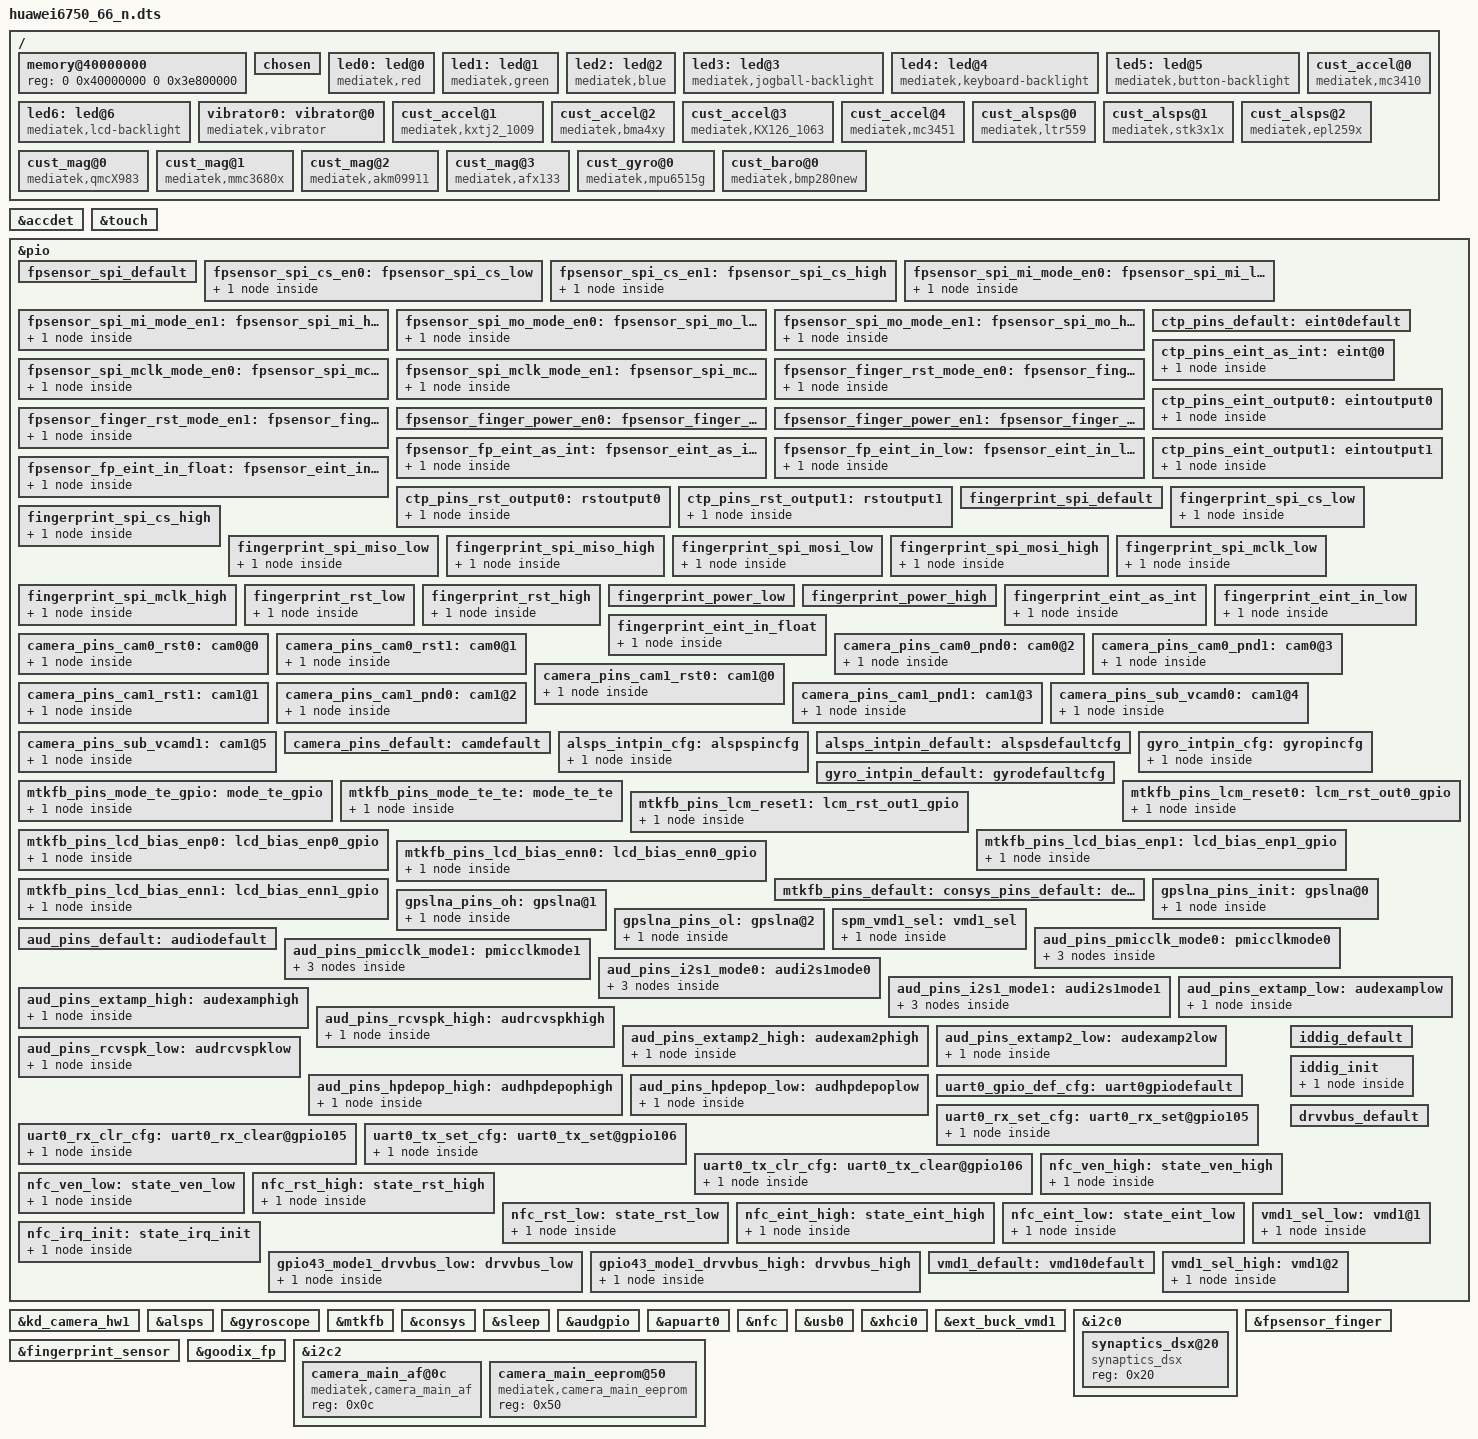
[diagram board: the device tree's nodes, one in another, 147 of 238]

/dts-v1/;

#include "mt6755.dtsi"
#include "cust.dtsi"
#include "ChipSailing_pin.dtsi"

/ {
    memory@40000000 {
        device_type = "memory";
        reg = <0 0x40000000 0 0x3e800000>;
    };
    /* chosen */
    chosen {
        bootargs = "console=tty0 console=ttyMT0,921600n1 root=/dev/ram initrd=0x44000000,0x4B434E loglevel=8";

        /* fpga may has no lk, we need to specify display info here */
        /* fb buffer is reserved using this dts by memory node above */
        atag,videolfb-fb_base_h = <0x0>;
        atag,videolfb-fb_base_l = <0x7E800000>;
        atag,videolfb-islcmfound = <1>;
        /* because no lk, so lcm is not inited */
        atag,videolfb-islcm_inited = <0>;
        atag,videolfb-fps= <6000>;
        atag,videolfb-vramSize= <0x01800000>;
        atag,videolfb-lcmname= "nt35695_fhd_dsi_cmd_truly_nt50358_drv";
    };
    led0:led@0 {
        compatible = "mediatek,red";
        led_mode = <3>;
        data = <1>;
        pwm_config = <0 0 0 0 0>;
    };
    led1:led@1 {
        compatible = "mediatek,green";
        led_mode = <3>;
        data = <2>;
        pwm_config = <0 0 0 0 0>;
    };
    led2:led@2 {
        compatible = "mediatek,blue";
        led_mode = <0>;
        data = <1>;
        pwm_config = <0 0 0 0 0>;
    };
    led3:led@3 {
        compatible = "mediatek,jogball-backlight";
        led_mode = <0>;
        data = <1>;
        pwm_config = <0 0 0 0 0>;
    };
    led4:led@4 {
        compatible = "mediatek,keyboard-backlight";
        led_mode = <0>;
        data = <1>;
        pwm_config = <0 0 0 0 0>;
    };
    led5:led@5 {
        compatible = "mediatek,button-backlight";
        led_mode = <0>;
        data = <1>;
        pwm_config = <0 0 0 0 0>;
    };
    led6:led@6 {
        compatible = "mediatek,lcd-backlight";
        led_mode = <4>;
        data = <1>;
        pwm_config = <0 0 0 0 0>;
    };
    vibrator0:vibrator@0 {
        compatible = "mediatek,vibrator";
        vib_timer = <25>;
        vib_limit = <9>;
        vib_vol= <5>;
    };
/*  start sensor */
    cust_accel@0 {
                compatible                              = "mediatek,mc3410";
                i2c_num                         = <1>;
                i2c_addr                                = <0x4c 0 0 0>;
                direction                               = <6>;
                power_id                                = <0xffff>;
                power_vol                               = <0>;
                firlen                                  = <0>;
                is_batch_supported                      = <0>;
                //calib_enable                    = <1>;
                //auto_calib_enable                       = <0>;
        };

    cust_accel@1 {
        compatible = "mediatek,kxtj2_1009";
        i2c_num = <1>;
        /* i2c_addr = <0x4c 0 0 0>; */
        direction = <4>;
        power_id = <0xffff>;
        power_vol = <0>;
        firlen = <0>;
        is_batch_supported = <0>;
        };
	cust_accel@2 {
        compatible = "mediatek,bma4xy";
        i2c_num = <1>;
        /* i2c_addr = <0x4c 0 0 0>; */
        direction = <4>;
        power_id = <0xffff>;
        power_vol = <0>;
        firlen = <0>;
        is_batch_supported = <0>;
        };

        cust_accel@3 {
        compatible = "mediatek,KX126_1063";
        i2c_num = <1>;
        //i2c_addr = <0x4c 0 0 0>;
        direction = <4>;
        power_id = <0xffff>;
        power_vol = <0>;
        firlen = <0>;
        is_batch_supported = <0>;
        };


        cust_accel@4 {
        compatible = "mediatek,mc3451";
        i2c_num = <1>;
        //i2c_addr = <0x4c 0 0 0>;
        direction = <4>;
        power_id = <0xffff>;
        power_vol = <0>;
        firlen = <0>;
        is_batch_supported = <0>;
        };
	cust_alsps@0 {
                compatible                              = "mediatek,ltr559";
                i2c_num                         = <1>;
                i2c_addr                                = <0x23 0 0 0>;
                polling_mode_ps                 = <0>;
                polling_mode_als                = <1>;
                power_id                                = <0xffff>;
                power_vol                               = <0>;
                als_level = <
                                        0  119  275  455  896  1507  2116    2661
                                        0  133  304   502  1004  2005  3058 4000
                                        0  133  304   502  1004  2005  3058 4000
                                        0  85  194  320  630  1059  1667    2210
                                        0  133  304   502  1004  2005  3058 4000
                                        0  133  304   502  1004  2005  3058 4000
                                         >;
                als_value = < 0  133  304  502   1004  2005  3058   4000 >;
                ps_threshold_high               =  <1000>;
                ps_threshold_low                =  <800>;
                is_batch_supported_ps   = <0>;
                is_batch_supported_als  = <0>;
                /*
                als_calib_enable = <1>;
                als_ch0_expect               =  <1000>;
                als_ch1_expect               =  <800>;
                */
                };

    cust_alsps@1 {
        compatible              = "mediatek,stk3x1x";
        i2c_num             = <1>;
        i2c_addr                = <0x48 0 0 0>;
        polling_mode_ps         = <0>;
        polling_mode_als        = <1>;
        power_id                = <0xffff>;
        power_vol               = <0>;
        als_level = <
                    0  44   90    212    442    762    922   1100
                    0  50   110   291    599    1295   2052   2807
                    0  74   150   348    698    1292   2205   2890
                    0  63   144   237    445    724     991   1231
                    0  72   163   258    560    1576   2400   3152
                    0  112  240   475    746    1719   2552   3333
                      >;
        als_value = < 0  100  200  500   1000  2000  3000   4000 >;
        state_val       =  <0>;
        psctrl_val      =  <0x31>;
        alsctrl_val = <0x38>;
        ledctrl_val = <0xFF>;
        wait_val        = <0xF>;
        ps_threshold_high       =  <1700>;
        ps_threshold_low        =  <1500>;
        is_batch_supported_ps   = <0>;
        is_batch_supported_als  = <0>;
        /*
        als_calib_enable = <1>;
        als_ch0_expect               =  <1000>;
        als_ch1_expect                =  <800>;
        */
        };
    cust_alsps@2 {
                compatible                              = "mediatek,epl259x";
                i2c_num                         = <1>;
                i2c_addr                                = <0x49 0 0 0>;
                polling_mode_ps                 = <0>;
                polling_mode_als                = <1>;
                power_id                                = <0xffff>;
                power_vol                               = <0>;
                als_level = <
                                        0  119  275  455  896  1507  2116    2661
                                        0  133  304   502  1004  2005  3058 4000
                                        0  133  304   502  1004  2005  3058 4000
                                        0  85  194  320  630  1059  1667    2210
                                        0  133  304   502  1004  2005  3058 4000
                                        0  133  304   502  1004  2005  3058 4000
                                         >;
                als_value = < 0  133  304  502   1004  2005  3058   4000 >;
                ps_threshold_high               =  <1000>;
                ps_threshold_low                =  <800>;
                als_threshold_high               =  <2000>;
                als_threshold_low                =  <1800>;
                is_batch_supported_ps   = <0>;
                is_batch_supported_als  = <0>;
                /*
                als_calib_enable = <1>;
                als_ch0_expect               =  <1000>;
                als_ch1_expect               =  <800>;
                */
                };

    cust_mag@0 {
        compatible                      = "mediatek,qmcX983";
        i2c_num                         = <1>;
        /* i2c_addr                     = <0x0F 0 0 0>; */
        direction                       = <3>;
        power_id                        = <0xffff>;
        power_vol                       = <0>;
        /* is_batch_supported           = <0>; */
        };

	cust_mag@1 {
        compatible                      = "mediatek,mmc3680x";
        i2c_num                         = <1>;
        /*i2c_addr                      = <0x0F 0 0 0>;*/
        direction                       = <2>;
        power_id                        = <0xffff>;
        power_vol                       = <0>;
        /* is_batch_supported           = <0>; */
        };
        cust_mag@2 {
        compatible                      = "mediatek,akm09911";
        i2c_num                         = <1>;
        /*i2c_addr                      = <0x0F 0 0 0>;*/
        direction                       = <2>;
        power_id                        = <0xffff>;
        power_vol                       = <0>;
        /* is_batch_supported           = <0>; */
        };

	cust_mag@3 {
        compatible                      = "mediatek,afx133";
        i2c_num                         = <1>;
        /*i2c_addr                      = <0x0F 0 0 0>;*/
        direction                       = <1>;
        power_id                        = <0xffff>;
        power_vol                       = <0>;
        /* is_batch_supported           = <0>; */
        };
    cust_gyro@0 {
    compatible          = "mediatek,mpu6515g";
    i2c_num             = <1>;
    /* i2c_addr         = <0x68 0 0 0>; */
    direction           = <6>;
    power_id            = <0xffff>;
    power_vol           = <0>;
    firlen              = <0>;
    is_batch_supported      = <0>;
    };

    cust_baro@0 {
    compatible          = "mediatek,bmp280new";
    i2c_num             = <1>;
    /* i2c_addr         = <0x68 0 0 0>; */
    direction           = <0>;
    power_id            = <0xffff>;
    power_vol           = <0>;
    firlen              = <32>;
    is_batch_supported      = <0>;
    };
/* end sensor */
};
&accdet {
        accdet-mic-vol = <7>;
        headset-mode-setting = <0x500 0x500 1 0x3F0 0x800 0x800 0x200>;
        accdet-plugout-debounce = <20>;
        /*1:ACC mode, 2:low cost without in bias, 6:low cost with in bias*/
        accdet-mic-mode = <1>;
        /*0--MD_MAX--UP_MAX--DW_MAX*/
        headset-three-key-threshold = <0 110 220 500>;
        /*0--MD_MAX--VOICE_MAX--UP_MAX--DW_MAX*/
        headset-four-key-threshold = <0 59 123 195 450>;
};

/* TOUCH start */
&touch {
    tpd-resolution = <720 1280>;
    use-tpd-button = <0>;
    tpd-key-num = <3>;
    tpd-key-local= <139 172 158 0>;
    tpd-key-dim-local = <90 883 100 40 230 883 100 40 370 883 100 40 0 0 0 0>;
    tpd-max-touch-num = <5>;
    tpd-filter-enable = <0>;
    tpd-filter-pixel-density = <146>;
    tpd-filter-custom-prameters = <0 0 0 0 0 0 0 0 0 0 0 0>;
    tpd-filter-custom-speed = <0 0 0>;
    pinctrl-names = "default", "state_eint_as_int", "state_eint_output0", "state_eint_output1",
        "state_rst_output0", "state_rst_output1";
    pinctrl-0 = <&ctp_pins_default>;
    pinctrl-1 = <&ctp_pins_eint_as_int>;
    pinctrl-2 = <&ctp_pins_eint_output0>;
    pinctrl-3 = <&ctp_pins_eint_output1>;
    pinctrl-4 = <&ctp_pins_rst_output0>;
    pinctrl-5 = <&ctp_pins_rst_output1>;
    status = "okay";
};
&pio {

    fpsensor_spi_default: fpsensor_spi_default {
    };

    fpsensor_spi_cs_en0: fpsensor_spi_cs_low {
        pins_cmd_dat {
            pins = <PINMUX_GPIO96__FUNC_SPI0_CSB>;
            slew-rate = <1>;
            output-low;
        };
    };
    fpsensor_spi_cs_en1: fpsensor_spi_cs_high {
        pins_cmd_dat {
            pins = <PINMUX_GPIO96__FUNC_SPI0_CSB>;
            slew-rate = <1>;
            output-high;
        };
    };
    fpsensor_spi_mi_mode_en0: fpsensor_spi_mi_low {
        pins_cmd_dat {
            pins = <PINMUX_GPIO95__FUNC_SPI0_MI>;
            slew-rate = <0>;
            bias-pull-up = <00>;
        };
    };
    fpsensor_spi_mi_mode_en1: fpsensor_spi_mi_high {
        pins_cmd_dat {
            pins = <PINMUX_GPIO95__FUNC_SPI0_MI>;
            bias-disable;
        };
    };
    fpsensor_spi_mo_mode_en0: fpsensor_spi_mo_low {
        pins_cmd_dat {
            pins = <PINMUX_GPIO97__FUNC_SPI0_MO>;
            slew-rate = <1>;
            output-low;
        };
    };
    fpsensor_spi_mo_mode_en1: fpsensor_spi_mo_high {
        pins_cmd_dat {
            pins = <PINMUX_GPIO97__FUNC_SPI0_MO>;
            slew-rate = <1>;
            output-high;
        };
    };
        fpsensor_spi_mclk_mode_en0: fpsensor_spi_mclk_low {
        pins_cmd_dat {
            pins = <PINMUX_GPIO98__FUNC_SPI0_CLK>;
            slew-rate = <1>;
            output-low;
        };
    };
    fpsensor_spi_mclk_mode_en1: fpsensor_spi_mclk_high {
        pins_cmd_dat {
            pins = <PINMUX_GPIO98__FUNC_SPI0_CLK>;
            slew-rate = <1>;
            output-high;
        };
    };
    fpsensor_finger_rst_mode_en0: fpsensor_finger_rst_low {
        pins_cmd_dat {
            pins = <PINMUX_GPIO18__FUNC_GPIO18>;
            slew-rate = <1>;
            output-low;
        };
    };
    fpsensor_finger_rst_mode_en1: fpsensor_finger_rst_high {
        pins_cmd_dat {
            pins = <PINMUX_GPIO18__FUNC_GPIO18>;
            slew-rate = <1>;
            output-high;
        };
    };
    fpsensor_finger_power_en0: fpsensor_finger_power_low {

    };
    fpsensor_finger_power_en1: fpsensor_finger_power_high {

    };
    fpsensor_fp_eint_as_int: fpsensor_eint_as_int {
        pins_cmd_dat {
            pins = <PINMUX_GPIO0__FUNC_GPIO0>;
            slew-rate = <0>;
            bias-disable;
        };
    };
    fpsensor_fp_eint_in_low: fpsensor_eint_in_low {
        pins_cmd_dat {
            pins = <PINMUX_GPIO0__FUNC_GPIO0>;
            slew-rate = <0>;
            bias-pull-down = <00>;
        };
    };
    fpsensor_fp_eint_in_float: fpsensor_eint_in_float {
        pins_cmd_dat {
            pins = <PINMUX_GPIO0__FUNC_GPIO0>;
            slew-rate = <0>;
            bias-disable;
        };
    };
/*
    fpsensor_finger_cs_mode_en0: fpsensor_finger_cs_low {
        pins_cmd_dat {
            pins = <PINMUX_GPIO96__FUNC_GPIO96>;
            slew-rate = <1>;
            output-low;
        };
    };
    fpsensor_finger_cs_mode_en1: fpsensor_finger_cs_high {
        pins_cmd_dat {
            pins = <PINMUX_GPIO96__FUNC_GPIO96>;
            slew-rate = <1>;
            output-high;
        };
    };
*/

    ctp_pins_default: eint0default {
    };
    ctp_pins_eint_as_int: eint@0 {
        pins_cmd_dat {
            pins = <PINMUX_GPIO1__FUNC_GPIO1>;
            slew-rate = <0>;
            bias-pull-up;
        };
    };
    ctp_pins_eint_output0: eintoutput0 {
        pins_cmd_dat {
            pins = <PINMUX_GPIO1__FUNC_GPIO1>;
            slew-rate = <1>;
            output-low;
        };
    };
    ctp_pins_eint_output1: eintoutput1 {
        pins_cmd_dat {
            pins = <PINMUX_GPIO1__FUNC_GPIO1>;
            slew-rate = <1>;
            output-high;
        };
    };
    ctp_pins_rst_output0: rstoutput0 {
        pins_cmd_dat {
            pins = <PINMUX_GPIO10__FUNC_GPIO10>;
            slew-rate = <1>;
            output-low;
        };
    };
    ctp_pins_rst_output1: rstoutput1 {
        pins_cmd_dat {
            pins = <PINMUX_GPIO10__FUNC_GPIO10>;
            slew-rate = <1>;
            output-high;
        };
    };
};
/* TOUCH end */
&pio {

    fingerprint_spi_default: fingerprint_spi_default {
    };

    fingerprint_spi_cs_low: fingerprint_spi_cs_low {
        pins_cmd_dat {
            pins = <PINMUX_GPIO96__FUNC_SPI0_CSB>;
            slew-rate = <1>;
            output-low;
        };
    };
    fingerprint_spi_cs_high: fingerprint_spi_cs_high {
        pins_cmd_dat {
            pins = <PINMUX_GPIO96__FUNC_SPI0_CSB>;
            slew-rate = <1>;
            output-high;
        };
    };
    fingerprint_spi_miso_low: fingerprint_spi_miso_low {
        pins_cmd_dat {
            pins = <PINMUX_GPIO95__FUNC_SPI0_MI>;
            slew-rate = <0>;
            bias-pull-up = <00>;
        };
    };
    fingerprint_spi_miso_high: fingerprint_spi_miso_high {
        pins_cmd_dat {
            pins = <PINMUX_GPIO95__FUNC_SPI0_MI>;
            bias-disable;
        };
    };
    fingerprint_spi_mosi_low: fingerprint_spi_mosi_low {
        pins_cmd_dat {
            pins = <PINMUX_GPIO97__FUNC_SPI0_MO>;
            slew-rate = <1>;
            output-low;
        };
    };
    fingerprint_spi_mosi_high: fingerprint_spi_mosi_high {
        pins_cmd_dat {
            pins = <PINMUX_GPIO97__FUNC_SPI0_MO>;
            slew-rate = <1>;
            output-high;
        };
    };
    fingerprint_spi_mclk_low: fingerprint_spi_mclk_low {
        pins_cmd_dat {
            pins = <PINMUX_GPIO98__FUNC_SPI0_CLK>;
            slew-rate = <1>;
            output-low;
        };
    };
    fingerprint_spi_mclk_high: fingerprint_spi_mclk_high {
        pins_cmd_dat {
            pins = <PINMUX_GPIO98__FUNC_SPI0_CLK>;
            slew-rate = <1>;
            output-high;
        };
    };
    fingerprint_rst_low: fingerprint_rst_low {
        pins_cmd_dat {
            pins = <PINMUX_GPIO18__FUNC_GPIO18>;
            slew-rate = <1>;
            output-low;
        };
    };
    fingerprint_rst_high: fingerprint_rst_high {
        pins_cmd_dat {
            pins = <PINMUX_GPIO18__FUNC_GPIO18>;
            slew-rate = <1>;
            output-high;
        };
    };
    fingerprint_power_low: fingerprint_power_low {

    };
    fingerprint_power_high: fingerprint_power_high {

    };
    fingerprint_eint_as_int: fingerprint_eint_as_int {
        pins_cmd_dat {
            pins = <PINMUX_GPIO0__FUNC_GPIO0>;
            slew-rate = <0>;
            bias-disable;
        };
    };
    fingerprint_eint_in_low: fingerprint_eint_in_low {
        pins_cmd_dat {
            pins = <PINMUX_GPIO0__FUNC_GPIO0>;
            slew-rate = <0>;
            bias-pull-down = <00>;
        };
    };
    fingerprint_eint_in_float: fingerprint_eint_in_float {
        pins_cmd_dat {
            pins = <PINMUX_GPIO0__FUNC_GPIO0>;
            slew-rate = <0>;
            bias-disable;
        };
    };
/*
    fpsensor_finger_cs_mode_en0: fpsensor_finger_cs_low {
        pins_cmd_dat {
            pins = <PINMUX_GPIO96__FUNC_GPIO96>;
            slew-rate = <1>;
            output-low;
        };
    };
    fpsensor_finger_cs_mode_en1: fpsensor_finger_cs_high {
        pins_cmd_dat {
            pins = <PINMUX_GPIO96__FUNC_GPIO96>;
            slew-rate = <1>;
            output-high;
        };
    };
*/
};
/* CAMERA GPIO standardization */
&pio {
    camera_pins_cam0_rst0: cam0@0 {
        pins_cmd_dat {
            pins = <PINMUX_GPIO110__FUNC_GPIO110>;
            slew-rate = <1>; /*direction 0:in, 1:out*/
            output-low;/*direction out used only. output_low or high*/
        };
    };
    camera_pins_cam0_rst1: cam0@1 {
        pins_cmd_dat {
            pins = <PINMUX_GPIO110__FUNC_GPIO110>;
            slew-rate = <1>;
            output-high;
        };
    };
    camera_pins_cam0_pnd0: cam0@2 {
        pins_cmd_dat {
            pins = <PINMUX_GPIO107__FUNC_GPIO107>;
            slew-rate = <1>;
            output-low;
        };
    };
    camera_pins_cam0_pnd1: cam0@3 {
        pins_cmd_dat {
            pins = <PINMUX_GPIO107__FUNC_GPIO107>;
            slew-rate = <1>;
            output-high;
        };
    };
    camera_pins_cam1_rst0: cam1@0 {
        pins_cmd_dat {
            pins = <PINMUX_GPIO111__FUNC_GPIO111>;
            slew-rate = <1>; /*direction 0:in, 1:out*/
            output-low;/*direction out used only. output_low or high*/
        };
    };
    camera_pins_cam1_rst1: cam1@1 {
        pins_cmd_dat {
            pins = <PINMUX_GPIO111__FUNC_GPIO111>;
            slew-rate = <1>;
            output-high;
        };
    };
    camera_pins_cam1_pnd0: cam1@2 {
        pins_cmd_dat {
            pins = <PINMUX_GPIO108__FUNC_GPIO108>;
            slew-rate = <1>;
            output-low;
        };
    };
    camera_pins_cam1_pnd1: cam1@3 {
        pins_cmd_dat {
            pins = <PINMUX_GPIO108__FUNC_GPIO108>;
            slew-rate = <1>;
            output-high;
        };
    };
    camera_pins_sub_vcamd0: cam1@4 {
        pins_cmd_dat {
            pins = <PINMUX_GPIO82__FUNC_GPIO82>;
            slew-rate = <1>;
            output-low;
        };
    };
    camera_pins_sub_vcamd1: cam1@5 {
        pins_cmd_dat {
            pins = <PINMUX_GPIO82__FUNC_GPIO82>;
            slew-rate = <1>;
            output-high;
        };
    };
    /*camera_pins_cam_ldo_vcama_0: cam@vcama0 {
    };
    camera_pins_cam_ldo_vcama_1: cam@vcama1 {
    };*/
    camera_pins_default: camdefault {
    };

};

&kd_camera_hw1 {
    pinctrl-names = "default",
            "cam0_rst0", "cam0_rst1", "cam0_pnd0", "cam0_pnd1",
            "cam1_rst0", "cam1_rst1", "cam1_pnd0", "cam1_pnd1",
            "cam_ldo_sub_vcamd_0", "cam_ldo_sub_vcamd_1";
            /*"cam2_rst0", "cam2_rst1", "cam2_pnd0", "cam2_pnd1",
            "cam_ldo_vcama_0", "cam_ldo_vcama_1";*/
    pinctrl-0 = <&camera_pins_default>;
    pinctrl-1 = <&camera_pins_cam0_rst0>;
    pinctrl-2 = <&camera_pins_cam0_rst1>;
    pinctrl-3 = <&camera_pins_cam0_pnd0>;
    pinctrl-4 = <&camera_pins_cam0_pnd1>;
    pinctrl-5 = <&camera_pins_cam1_rst0>;
    pinctrl-6 = <&camera_pins_cam1_rst1>;
    pinctrl-7 = <&camera_pins_cam1_pnd0>;
    pinctrl-8 = <&camera_pins_cam1_pnd1>;
    pinctrl-9 = <&camera_pins_sub_vcamd0>;
    pinctrl-10 = <&camera_pins_sub_vcamd1>;
    /* for main2 */
    /*pinctrl-9 = <&camera_pins_cam2_rst0>;
    pinctrl-10 = <&camera_pins_cam2_rst1>;
    pinctrl-11 = <&camera_pins_cam2_pnd0>;
    pinctrl-12 = <&camera_pins_cam2_pnd1>;*/
    /* for ldo control by gpio */
    /*pinctrl-13 = <&camera_pins_cam_ldo_vcama_0>;
    pinctrl-14 = <&camera_pins_cam_ldo_vcama_1>;*/
    status = "okay";

};
/* CAMERA GPIO end */

&pio {
    alsps_intpin_cfg: alspspincfg {

        pins_cmd_dat {
            pins = <PINMUX_GPIO6__FUNC_GPIO6>;
            slew-rate = <0>;
            bias-pull-up = <00>;
        };
    };

    alsps_intpin_default: alspsdefaultcfg {

    };

    gyro_intpin_cfg: gyropincfg {

        pins_cmd_dat {
            pins = <PINMUX_GPIO4__FUNC_GPIO4>;
            slew-rate = <0>;
            bias-pull-down = <00>;
        };
    };

    gyro_intpin_default: gyrodefaultcfg {

    };
};

&alsps {
    pinctrl-names = "pin_default", "pin_cfg";
    pinctrl-0 = <&alsps_intpin_default>;
    pinctrl-1 = <&alsps_intpin_cfg>;
    status = "okay";
};

&gyroscope {
    pinctrl-names = "pin_default", "pin_cfg";
    pinctrl-0 = <&gyro_intpin_default>;
    pinctrl-1 = <&gyro_intpin_cfg>;
    status = "okay";
};

/* DISPSYS GPIO standardization */
&pio {

    mtkfb_pins_mode_te_gpio: mode_te_gpio {
        pins_cmd_dat {
            pins = <PINMUX_GPIO44__FUNC_GPIO44>;
        };
    };

    mtkfb_pins_mode_te_te: mode_te_te {
        pins_cmd_dat {
            pins = <PINMUX_GPIO44__FUNC_DSI_TE>;
        };
    };

    mtkfb_pins_lcm_reset0: lcm_rst_out0_gpio {
        pins_cmd_dat {
            pins = <PINMUX_GPIO158__FUNC_LCM_RST>;
            slew-rate = <1>;
            output-low;
        };
    };

    mtkfb_pins_lcm_reset1: lcm_rst_out1_gpio {
        pins_cmd_dat {
            pins = <PINMUX_GPIO158__FUNC_LCM_RST>;
            slew-rate = <1>;
            output-high;
        };
    };

    mtkfb_pins_lcd_bias_enp0: lcd_bias_enp0_gpio {
        pins_cmd_dat {
            pins = <PINMUX_GPIO12__FUNC_GPIO12>;
            slew-rate = <1>;
            output-low;
        };
    };

    mtkfb_pins_lcd_bias_enp1: lcd_bias_enp1_gpio {
        pins_cmd_dat {
            pins = <PINMUX_GPIO12__FUNC_GPIO12>;
            slew-rate = <1>;
            output-high;
        };
    };
/* +add by ontim */
    mtkfb_pins_lcd_bias_enn0: lcd_bias_enn0_gpio {
        pins_cmd_dat {
            pins = <PINMUX_GPIO11__FUNC_GPIO11>;
            slew-rate = <1>;
            output-low;
        };
    };

    mtkfb_pins_lcd_bias_enn1: lcd_bias_enn1_gpio {
        pins_cmd_dat {
            pins = <PINMUX_GPIO11__FUNC_GPIO11>;
            slew-rate = <1>;
            output-high;
        };
    };
/* -add by ontim */

    mtkfb_pins_default: default {
    };
};

/* +add by ontim */
&mtkfb {
    pinctrl-names = "default", "mode_te_gpio", "mode_te_te", "lcm_rst_out0_gpio",
    "lcm_rst_out1_gpio", "lcd_bias_enp0_gpio", "lcd_bias_enp1_gpio", "lcd_bias_enn0_gpio", "lcd_bias_enn1_gpio";
    pinctrl-0 = <&mtkfb_pins_default>;
    pinctrl-1 = <&mtkfb_pins_mode_te_gpio>;
    pinctrl-2 = <&mtkfb_pins_mode_te_te>;
    pinctrl-3 = <&mtkfb_pins_lcm_reset0>;
    pinctrl-4 = <&mtkfb_pins_lcm_reset1>;
    pinctrl-5 = <&mtkfb_pins_lcd_bias_enp0>;
    pinctrl-6 = <&mtkfb_pins_lcd_bias_enp1>;
    pinctrl-7 = <&mtkfb_pins_lcd_bias_enn0>;
    pinctrl-8 = <&mtkfb_pins_lcd_bias_enn1>;
    status = "okay";
};/* DISPSYS GPIO standardization end */
/* -add by ontim */

/* CONSYS GPIO standardization */
&pio {
    consys_pins_default: default {
    };

    gpslna_pins_init: gpslna@0 {
        pins_cmd_dat {
            pins = <PINMUX_GPIO114__FUNC_GPIO114>;
            slew-rate = <0>;
            bias-disable;
            output-low;
        };
    };

    gpslna_pins_oh: gpslna@1 {
        pins_cmd_dat {
            pins = <PINMUX_GPIO114__FUNC_GPIO114>;
            slew-rate = <1>;
            output-high;
        };
    };

    gpslna_pins_ol: gpslna@2 {
        pins_cmd_dat {
            pins = <PINMUX_GPIO114__FUNC_GPIO114>;
            slew-rate = <1>;
            output-low;
        };
    };
};

&consys {
    pinctrl-names = "default", "gps_lna_state_init", "gps_lna_state_oh", "gps_lna_state_ol";
    pinctrl-0 = <&consys_pins_default>;
    pinctrl-1 = <&gpslna_pins_init>;
    pinctrl-2 = <&gpslna_pins_oh>;
    pinctrl-3 = <&gpslna_pins_ol>;
    status = "okay";
};
/* CONSYS end */

/* SPM GPIO standardization */
&pio {
    spm_pins_default: default {
    };

    spm_vmd1_sel: vmd1_sel {
        pins_cmd_dat {
            pins = <PINMUX_GPIO115__FUNC_GPIO115>;
        };
    };

};

&sleep{
    pinctrl-names = "default", "vmd1_sel";
    pinctrl-0 = <&spm_pins_default>;
    pinctrl-1 = <&spm_vmd1_sel>;
    status = "okay";
};
/* SPM end */

/* AUDIO GPIO standardization */
&audgpio {
    pinctrl-names = "default", "audpmicclk-mode0", "audpmicclk-mode1",
        "audi2s1-mode0", "audi2s1-mode1", "extamp-pullhigh", "extamp-pulllow",
        /*"extamp2-pullhigh", "extamp2-pulllow",*/ "rcvspk-pullhigh",
        "rcvspk-pulllow","hpdepop-pullhigh","hpdepop-pulllow";
    pinctrl-0 = <&aud_pins_default>;
    pinctrl-1 = <&aud_pins_pmicclk_mode0>;
    pinctrl-2 = <&aud_pins_pmicclk_mode1>;
    pinctrl-3 = <&aud_pins_i2s1_mode0>;
    pinctrl-4 = <&aud_pins_i2s1_mode1>;
    pinctrl-5 = <&aud_pins_extamp_high>;
    pinctrl-6 = <&aud_pins_extamp_low>;
/*  pinctrl-7 = <&aud_pins_extamp2_high>;
    pinctrl-8 = <&aud_pins_extamp2_low>;  */
    pinctrl-7 = <&aud_pins_rcvspk_high>;
    pinctrl-8 = <&aud_pins_rcvspk_low>;
    pinctrl-9 = <&aud_pins_hpdepop_high>;
    pinctrl-10 = <&aud_pins_hpdepop_low>;
    status = "okay";
};

&pio {
    aud_pins_default: audiodefault {
    };

    aud_pins_pmicclk_mode0: pmicclkmode0 {
        pins_cmd0_dat {
            pins = <PINMUX_GPIO149__FUNC_GPIO149>;
        };
        pins_cmd1_dat {
            pins = <PINMUX_GPIO150__FUNC_GPIO150>;
            slew-rate = <0>;
            bias-pull-up = <00>;
        };
        pins_cmd2_dat {
            pins = <PINMUX_GPIO151__FUNC_GPIO151>;
        };
    };

    aud_pins_pmicclk_mode1: pmicclkmode1 {
        pins_cmd0_dat {
            pins = <PINMUX_GPIO149__FUNC_AUD_CLK_MOSI>;
        };
        pins_cmd1_dat {
            pins = <PINMUX_GPIO150__FUNC_AUD_DAT_MOSI>;
        };
        pins_cmd2_dat {
            pins = <PINMUX_GPIO151__FUNC_AUD_DAT_MISO>;
        };
    };

    aud_pins_i2s1_mode0: audi2s1mode0 {
        pins_cmd0_dat {
            pins = <PINMUX_GPIO7__FUNC_GPIO7>;
        };
        pins_cmd1_dat {
            pins = <PINMUX_GPIO6__FUNC_GPIO6>;
        };
        pins_cmd2_dat {
            pins = <PINMUX_GPIO5__FUNC_GPIO5>;
        };
    };

    aud_pins_i2s1_mode1: audi2s1mode1 {
        pins_cmd0_dat {
            pins = <PINMUX_GPIO7__FUNC_I2S0_DI>;
        };
        pins_cmd1_dat {
            pins = <PINMUX_GPIO6__FUNC_I2S0_LRCK>;
        };
        pins_cmd2_dat {
            pins = <PINMUX_GPIO5__FUNC_I2S0_BCK>;
        };
    };

    aud_pins_extamp_high: audexamphigh {
        pins_cmd_dat {
            pins = <PINMUX_GPIO22__FUNC_GPIO22>;
            slew-rate = <1>;
            output-high;
        };
    };

    aud_pins_extamp_low: audexamplow {
        pins_cmd_dat {
            pins = <PINMUX_GPIO22__FUNC_GPIO22>;
            slew-rate = <1>;
            output-low;
        };
    };
/*
    aud_pins_extamp2_high: audexam2phigh {
        pins_cmd_dat {
            pins = <PINMUX_GPIO54__FUNC_GPIO54>;
            slew-rate = <1>;
            output-high;
        };
    };
    aud_pins_extamp2_low: audexamp2low {
        pins_cmd_dat {
            pins = <PINMUX_GPIO54__FUNC_GPIO54>;
            slew-rate = <1>;
            output-low;
        };
    };
*/
    aud_pins_rcvspk_high: audrcvspkhigh {
        pins_cmd_dat {
            pins = <PINMUX_GPIO120__FUNC_GPIO120>;
            slew-rate = <1>;
            output-high;
        };
    };

    aud_pins_extamp2_high: audexam2phigh {
        pins_cmd_dat {
            pins = <PINMUX_GPIO54__FUNC_GPIO54>;
            slew-rate = <1>;
            output-high;
        };
    };
    aud_pins_extamp2_low: audexamp2low {
        pins_cmd_dat {
            pins = <PINMUX_GPIO54__FUNC_GPIO54>;
            slew-rate = <1>;
            output-low;
        };
    };

    aud_pins_rcvspk_high: audrcvspkhigh {
        pins_cmd_dat {
            pins = <PINMUX_GPIO120__FUNC_GPIO120>;
            slew-rate = <1>;
            output-high;
        };
    };

    aud_pins_rcvspk_low: audrcvspklow {
        pins_cmd_dat {
            pins = <PINMUX_GPIO120__FUNC_GPIO120>;
            slew-rate = <1>;
            output-low;
        };
    };

    aud_pins_hpdepop_high: audhpdepophigh {
        pins_cmd_dat {
            pins = <PINMUX_GPIO24__FUNC_GPIO24>;
            slew-rate = <1>;
            output-high;
        };
    };

    aud_pins_hpdepop_low: audhpdepoplow {
        pins_cmd_dat {
            pins = <PINMUX_GPIO24__FUNC_GPIO24>;
            slew-rate = <1>;
            output-low;
        };
    };
};
/* AUDIO end */

/* UART GPIO */
&apuart0 {
    pinctrl-names = "uart0_gpio_default",
            "uart0_rx_set",
            "uart0_rx_clear",
            "uart0_tx_set",
            "uart0_tx_clear";
    pinctrl-0 = <&uart0_gpio_def_cfg>;
    pinctrl-1 = <&uart0_rx_set_cfg>;
    pinctrl-2 = <&uart0_rx_clr_cfg>;
    pinctrl-3 = <&uart0_tx_set_cfg>;
    pinctrl-4 = <&uart0_tx_clr_cfg>;
    status = "okay";
};

&pio {
    /* UART GPIO Settings - Start */
    /* UART0: rx set, rx clear, tx clear, tx clear*/
    uart0_gpio_def_cfg:uart0gpiodefault {

    };
    uart0_rx_set_cfg:uart0_rx_set@gpio105 {
        pins_cmd_dat {
            pins = <PINMUX_GPIO105__FUNC_URXD0>;
        };
    };
    uart0_rx_clr_cfg:uart0_rx_clear@gpio105  {
        pins_cmd_dat {
            pins = <PINMUX_GPIO105__FUNC_GPIO105>;
            slew-rate = <1>;
            output-high;
        };
    };
    uart0_tx_set_cfg:uart0_tx_set@gpio106  {
        pins_cmd_dat {
            pins = <PINMUX_GPIO106__FUNC_UTXD0>;
        };
    };
    uart0_tx_clr_cfg:uart0_tx_clear@gpio106  {
        pins_cmd_dat {
            pins = <PINMUX_GPIO106__FUNC_GPIO106>;
            slew-rate = <1>;
            output-high;
        };
    };
};/* UART GPIO end */

/* NFC GPIO standardization */
&pio {
    nfc_default: default {

    };

    nfc_ven_high: state_ven_high {
        pins_cmd_dat {
            pins = <PINMUX_GPIO28__FUNC_GPIO28>;
            slew-rate = <1>;
            output-high;
        };
    };

    nfc_ven_low: state_ven_low {
        pins_cmd_dat {
            pins = <PINMUX_GPIO28__FUNC_GPIO28>;
            slew-rate = <1>;
            output-low;
        };
    };

    nfc_rst_high: state_rst_high {
        pins_cmd_dat {
            pins = <PINMUX_GPIO25__FUNC_GPIO25>;
            slew-rate = <1>;
            output-high;
        };
    };

    nfc_rst_low: state_rst_low {
        pins_cmd_dat {
            pins = <PINMUX_GPIO25__FUNC_GPIO25>;
            slew-rate = <1>;
            output-low;
        };
    };

    nfc_eint_high: state_eint_high {
        pins_cmd_dat {
            pins = <PINMUX_GPIO27__FUNC_GPIO27>;
            slew-rate = <1>;
            output-high;
        };
    };

    nfc_eint_low: state_eint_low {
        pins_cmd_dat {
            pins = <PINMUX_GPIO27__FUNC_GPIO27>;
            slew-rate = <1>;
            output-low;
        };
    };

    nfc_irq_init: state_irq_init {
        pins_cmd_dat {
            pins = <PINMUX_GPIO26__FUNC_GPIO26>;
            slew-rate = <0>;
            bias-pull-down = <00>;
        };
    };
};

&nfc {
    pinctrl-names = "default", "ven_high", "ven_low", "rst_high", "rst_low", "eint_high", "eint_low", "irq_init";
    pinctrl-0 = <&nfc_default>;
    pinctrl-1 = <&nfc_ven_high>;
    pinctrl-2 = <&nfc_ven_low>;
    pinctrl-3 = <&nfc_rst_high>;
    pinctrl-4 = <&nfc_rst_low>;
    pinctrl-5 = <&nfc_eint_high>;
    pinctrl-6 = <&nfc_eint_low>;
    pinctrl-7 = <&nfc_irq_init>;
    status = "okay";
};
/* NFC end */




&pio {
    iddig_default: iddig_default {
    };

    iddig_init: iddig_init {
        pins_cmd_dat {
            pins = <PINMUX_GPIO23__FUNC_IDDIG>;
            slew-rate = <0>;
            bias-pull-up = <00>;
        };
    };
};

&pio {
    drvvbus_default: drvvbus_default {
    };

    gpio43_mode1_drvvbus_low: drvvbus_low {
        pins_cmd_dat {
            pins = <PINMUX_GPIO43__FUNC_USB_DRVVBUS>;
            slew-rate = <1>;
            output-low;
        };
    };

    gpio43_mode1_drvvbus_high: drvvbus_high {
        pins_cmd_dat {
            pins = <PINMUX_GPIO43__FUNC_USB_DRVVBUS>;
            slew-rate = <1>;
            output-high;
        };
    };
};

&usb0 {
    pinctrl-names = "iddig_default", "iddig_init";
    pinctrl-0 = <&iddig_default>;
    pinctrl-1 = <&iddig_init>;
    status = "okay";
};

&xhci0 {
    pinctrl-names = "drvvbus_default", "drvvbus_low", "drvvbus_high";
    pinctrl-0 = <&drvvbus_default>;
    pinctrl-1 = <&gpio43_mode1_drvvbus_low>;
    pinctrl-2 = <&gpio43_mode1_drvvbus_high>;
    status = "okay";
};
/*
&i2c1 {

    gyro@68 {
        compatible = "mediatek,gyro";
        reg = <0x69>;
        status = "okay";
    };

    gsensor@68 {
        compatible = "mediatek,gsensor";
        reg = <0x68>;
        status = "okay";
    };
};
*/
&ext_buck_vmd1 {
    pinctrl-names = "default", "vmd1_sel_low", "vmd1_sel_high";

    pinctrl-0 = <&vmd1_default>;
    pinctrl-1 = <&vmd1_sel_low>;
    pinctrl-2 = <&vmd1_sel_high>;
};

&pio {
    vmd1_default: vmd10default {
    };

    vmd1_sel_low: vmd1@1 {
        pins_cmd_dat {
            pins = <PINMUX_GPIO115__FUNC_GPIO115>;
            slew-rate = <1>;
            output-low;
        };
    };

    vmd1_sel_high: vmd1@2 {
        pins_cmd_dat {
            pins = <PINMUX_GPIO115__FUNC_GPIO115>;
            slew-rate = <1>;
            output-high;
        };
    };
};

/* add by ontim for I2C devices*/
&i2c0 {
    synaptics_dsx@20 {
        compatible = "synaptics_dsx";
        reg = <0x20>;
        status = "okay";
    };
};


&fpsensor_finger {
    interrupt-parent = <&eintc>;
    interrupts = <0 IRQ_TYPE_EDGE_RISING>;
    debounce = <0 0>;
    pinctrl-names = "fpsensor_spi_default", "fpsensor_spi_cs_low","fpsensor_spi_cs_high","fpsensor_spi_mi_low","fpsensor_spi_mi_high",
                    "fpsensor_spi_mo_low","fpsensor_spi_mo_high","fpsensor_spi_mclk_low","fpsensor_spi_mclk_high",
                    "fpsensor_finger_rst_low","fpsensor_finger_rst_high","fpsensor_finger_power_low","fpsensor_finger_power_high",
                    "fpsensor_eint","fpsensor_eint_in_low","fpsensor_eint_in_float"/*,"fpsensor_finger_cs_low","fpsensor_finger_cs_high"*/;
    pinctrl-0 = <&fpsensor_spi_default>;
    pinctrl-1 = <&fpsensor_spi_cs_en0>;
    pinctrl-2 = <&fpsensor_spi_cs_en1>;
    pinctrl-3 = <&fpsensor_spi_mi_mode_en0>;
    pinctrl-4 = <&fpsensor_spi_mi_mode_en1>;
    pinctrl-5 = <&fpsensor_spi_mo_mode_en0>;
    pinctrl-6 = <&fpsensor_spi_mo_mode_en1>;
    pinctrl-7 = <&fpsensor_spi_mclk_mode_en0>;
    pinctrl-8 = <&fpsensor_spi_mclk_mode_en1>;
    pinctrl-9 = <&fpsensor_finger_rst_mode_en0>;
    pinctrl-10 = <&fpsensor_finger_rst_mode_en1>;
    pinctrl-11 = <&fpsensor_finger_power_en0>;
    pinctrl-12 = <&fpsensor_finger_power_en1>;
    pinctrl-13 = <&fpsensor_fp_eint_as_int>;
    pinctrl-14 = <&fpsensor_fp_eint_in_low>;
    pinctrl-15 = <&fpsensor_fp_eint_in_float>;
    /*pinctrl-16 = <&fpsensor_finger_cs_mode_en0>;
    pinctrl-17 = <&fpsensor_finger_cs_mode_en1>;*/
    status = "okay";
};
&fingerprint_sensor {
    interrupt-parent = <&eintc>;
    interrupts = <0 IRQ_TYPE_EDGE_RISING>;
    debounce = <0 0>;
        fingerprint,navigation_adjust1 = <1>;

    pinctrl-names = "fingerprint_spi_default", "fingerprint_spi_cs_low","fingerprint_spi_cs_high","fingerprint_spi_miso_low","fingerprint_spi_miso_high",
                    "fingerprint_spi_mosi_low","fingerprint_spi_mosi_high","fingerprint_spi_mclk_low","fingerprint_spi_mclk_high",
                    "fingerprint_rst_low","fingerprint_rst_high","fingerprint_power_low","fingerprint_power_high",
                    "fingerprint_eint_as_int","fingerprint_eint_in_low","fingerprint_eint_in_float";
    pinctrl-0 = <&fingerprint_spi_default>;
    pinctrl-1 = <&fingerprint_spi_cs_low>;
    pinctrl-2 = <&fingerprint_spi_cs_high>;
    pinctrl-3 = <&fingerprint_spi_miso_low>;
    pinctrl-4 = <&fingerprint_spi_miso_high>;
    pinctrl-5 = <&fingerprint_spi_mosi_low>;
    pinctrl-6 = <&fingerprint_spi_mosi_high>;
    pinctrl-7 = <&fingerprint_spi_mclk_low>;
    pinctrl-8 = <&fingerprint_spi_mclk_high>;
    pinctrl-9 = <&fingerprint_rst_low>;
    pinctrl-10 = <&fingerprint_rst_high>;
    pinctrl-11 = <&fingerprint_power_low>;
    pinctrl-12 = <&fingerprint_power_high>;
    pinctrl-13 = <&fingerprint_eint_as_int>;
    pinctrl-14 = <&fingerprint_eint_in_low>;
    pinctrl-15 = <&fingerprint_eint_in_float>;
    status = "okay";
};
&goodix_fp {
    pinctrl-names = "cs_finger_pins_default", "cs_finger_reset_en0","cs_finger_reset_en1","cs_finger_spi0_mi_as_spi0_mi","cs_finger_spi0_mi_as_gpio",
                    "cs_finger_spi0_mo_as_spi0_mo","cs_finger_spi0_mo_as_gpio","cs_finger_spi0_clk_as_spi0_clk","cs_finger_spi0_clk_as_gpio","cs_finger_spi0_cs_as_spi0_cs",
                    "cs_finger_spi0_cs_as_gpio","cs_finger_int_as_int","cs_finger_eint_pull_down","cs_finger_eint_pull_disable","cs_finger_pwr_off", "cs_finger_pwr_on";
    pinctrl-0 = <&cs_finger_pins_default>;
    pinctrl-1 = <&cs_finger_reset_en0>;
    pinctrl-2 = <&cs_finger_reset_en1>;
    pinctrl-3 = <&cs_finger_spi0_mi_as_spi0_mi>;
    pinctrl-4 = <&cs_finger_spi0_mi_as_gpio>;
    pinctrl-5 = <&cs_finger_spi0_mo_as_spi0_mo>;
    pinctrl-6 = <&cs_finger_spi0_mo_as_gpio>;
    pinctrl-7 = <&cs_finger_spi0_clk_as_spi0_clk>;
    pinctrl-8= <&cs_finger_spi0_clk_as_gpio>;
    pinctrl-9= <&cs_finger_spi0_cs_as_spi0_cs>;
    pinctrl-10= <&cs_finger_spi0_cs_as_gpio>;
    pinctrl-11= <&cs_finger_int_as_int>;
    pinctrl-12= <&cs_finger_eint_pull_down>;
    pinctrl-13= <&cs_finger_eint_pull_disable>;
    pinctrl-14= <&cs_finger_pwr_off>;
    pinctrl-15= <&cs_finger_pwr_on>;

    interrupt-parent = <&eintc>;
    interrupts = <__CS_FINGERPRINT_EINT_EN_PIN_NUM__  IRQ_TYPE_EDGE_RISING>;
    debounce = <__CS_FINGERPRINT_EINT_EN_PIN_NUM__  0>;
};

&i2c2 {
    camera_main_af@0c {
        compatible = "mediatek,camera_main_af";
        reg = <0x0c>;
    };
    camera_main_eeprom@50 {
        compatible = "mediatek,camera_main_eeprom";
        reg = <0x50>;
    };
};

